# STM32N657 register map
File version: 1.0
CPU: CM55 r0p1, little endian, no MPU, FPU, vendor SysTick, 8 interrupt priority bits
Registers are 32-bit, read-write, reset 0x0 unless marked. A register's access mark holds for its fields unless they carry their own. Offsets are from the block's base; [hi:lo] are bit positions; 'fields as' and 'values as' point back to an identical list.

## RTC — Real-time clock
Base 0x46004000
Same registers: RTC_S 0x56004000
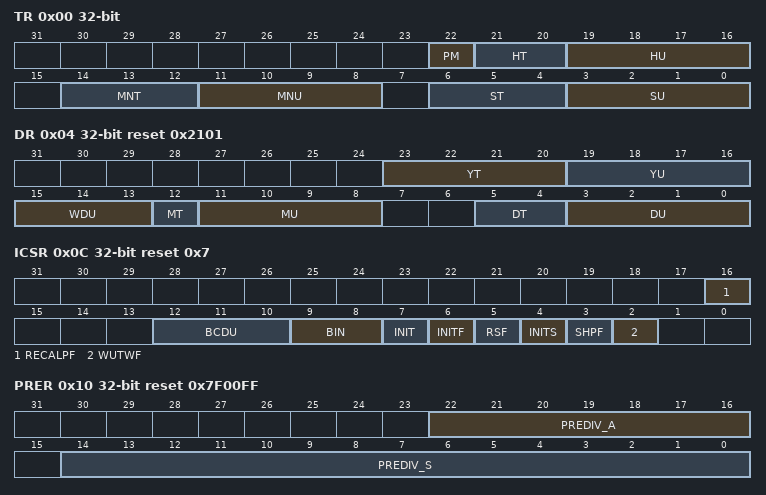
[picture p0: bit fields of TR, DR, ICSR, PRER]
0x00 TR — RTC time register
  [22] PM — AM/PM notation
  [21:20] HT — Hour tens in BCD format
  [19:16] HU — Hour units in BCD format
  [14:12] MNT — Minute tens in BCD format
  [11:8] MNU — Minute units in BCD format
  [6:4] ST — Second tens in BCD format
  [3:0] SU — Second units in BCD format
0x04 DR reset 0x2101 — RTC date register
  [23:20] YT — Year tens in BCD format
  [19:16] YU — Year units in BCD format
  [15:13] WDU — Week day units
  [12] MT — Month tens in BCD format
  [11:8] MU — Month units in BCD format
  [5:4] DT — Date tens in BCD format
  [3:0] DU — Date units in BCD format
0x08 SSR ro — RTC subsecond register
  [31:0] SS — Synchronous binary counter
0x0C ICSR access per field reset 0x7 — RTC initialization control and status register
  [16] RECALPF ro — Recalibration pending Flag
  [12:10] BCDU rw — BCD update (BIN = 10 or 11)
  [9:8] BIN rw — Binary mode
  [7] INIT rw — Initialization mode
  [6] INITF ro — Initialization flag
  [5] RSF rw — Registers synchronization flag
  [4] INITS ro — Initialization status flag
  [3] SHPF ro — Shift operation pending
  [2] WUTWF ro — Wake-up timer write flag
0x10 PRER reset 0x7F00FF — RTC prescaler register
  [22:16] PREDIV_A — Asynchronous prescaler factor
  [14:0] PREDIV_S — Synchronous prescaler factor
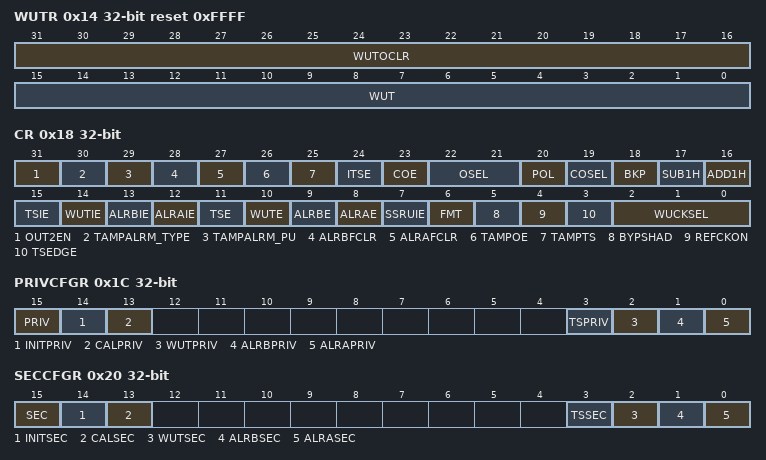
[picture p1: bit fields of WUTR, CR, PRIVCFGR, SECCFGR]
0x14 WUTR reset 0xFFFF — RTC wake-up timer register
  [31:16] WUTOCLR — Wake-up auto-reload output clear value
  [15:0] WUT — Wake-up auto-reload value bits
0x18 CR access per field — RTC control register
  [31] OUT2EN rw — RTC_OUT2 output enable
  [30] TAMPALRM_TYPE rw — TAMPALRM output type
  [29] TAMPALRM_PU rw — TAMPALRM pull-up enable
  [28] ALRBFCLR rw — Alarm B flag automatic clear
  [27] ALRAFCLR rw — Alarm A flag automatic clear
  [26] TAMPOE rw — Tamper detection output enable on TAMPALRM
  [25] TAMPTS rw — Activate timestamp on tamper detection event
  [24] ITSE rw — timestamp on internal event enable
  [23] COE rw — Calibration output enable
  [22:21] OSEL rw — Output selection
  [20] POL rw — Output polarity
  [19] COSEL rw — Calibration output selection
  [18] BKP rw — Backup
  [17] SUB1H wo — Subtract 1 hour (winter time change)
  [16] ADD1H wo — Add 1 hour (summer time change)
  [15] TSIE rw — Timestamp interrupt enable
  [14] WUTIE rw — Wake-up timer interrupt enable
  [13] ALRBIE rw — Alarm B interrupt enable
  [12] ALRAIE rw — Alarm A interrupt enable
  [11] TSE rw — timestamp enable
  [10] WUTE rw — Wake-up timer enable
  [9] ALRBE rw — Alarm B enable
  [8] ALRAE rw — Alarm A enable
  [7] SSRUIE rw — SSR underflow interrupt enable
  [6] FMT rw — Hour format
  [5] BYPSHAD rw — Bypass the shadow registers
  [4] REFCKON rw — RTC_REFIN reference clock detection enable (50 or 60 Hz)
  [3] TSEDGE rw — Timestamp event active edge
  [2:0] WUCKSEL rw — ck_wut wake-up clock selection
0x1C PRIVCFGR — RTC privilege mode control register
  [15] PRIV — RTC privilege protection
  [14] INITPRIV — Initialization privilege protection
  [13] CALPRIV — Shift register, Delight saving, calibration and reference clock privilege protection
  [3] TSPRIV — Timestamp privilege protection
  [2] WUTPRIV — Wake-up timer privilege protection
  [1] ALRBPRIV — Alarm B privilege protection
  [0] ALRAPRIV — Alarm A and SSR underflow privilege protection
0x20 SECCFGR — RTC secure configuration register
  [15] SEC — RTC global protection
  [14] INITSEC — Initialization protection
  [13] CALSEC — Shift register, daylight saving, calibration and reference clock protection
  [3] TSSEC — Timestamp protection
  [2] WUTSEC — Wake-up timer protection
  [1] ALRBSEC — Alarm B protection
  [0] ALRASEC — Alarm A and SSR underflow protection
0x24 WPR wo — RTC write protection register
  [7:0] KEY — Write protection key
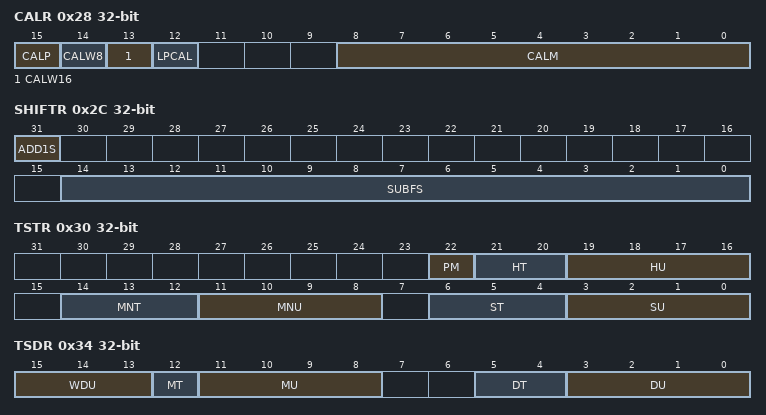
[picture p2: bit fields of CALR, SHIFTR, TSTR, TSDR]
0x28 CALR — RTC calibration register
  [15] CALP — Increase frequency of RTC by 488.5 ppm
  [14] CALW8 — Use an 8-second calibration cycle period
  [13] CALW16 — Use a 16-second calibration cycle period
  [12] LPCAL — RTC low-power mode
  [8:0] CALM — Calibration minus
0x2C SHIFTR wo — RTC shift control register
  [31] ADD1S — Add one second
  [14:0] SUBFS — Subtract a fraction of a second
0x30 TSTR ro — RTC timestamp time register
  [22] PM — AM/PM notation
  [21:20] HT — Hour tens in BCD format.
  [19:16] HU — Hour units in BCD format.
  [14:12] MNT — Minute tens in BCD format.
  [11:8] MNU — Minute units in BCD format.
  [6:4] ST — Second tens in BCD format.
  [3:0] SU — Second units in BCD format.
0x34 TSDR ro — RTC timestamp date register
  [15:13] WDU — Week day units
  [12] MT — Month tens in BCD format
  [11:8] MU — Month units in BCD format
  [5:4] DT — Date tens in BCD format
  [3:0] DU — Date units in BCD format
0x38 TSSSR ro — RTC timestamp subsecond register
  [31:0] SS — Subsecond value/synchronous binary counter values
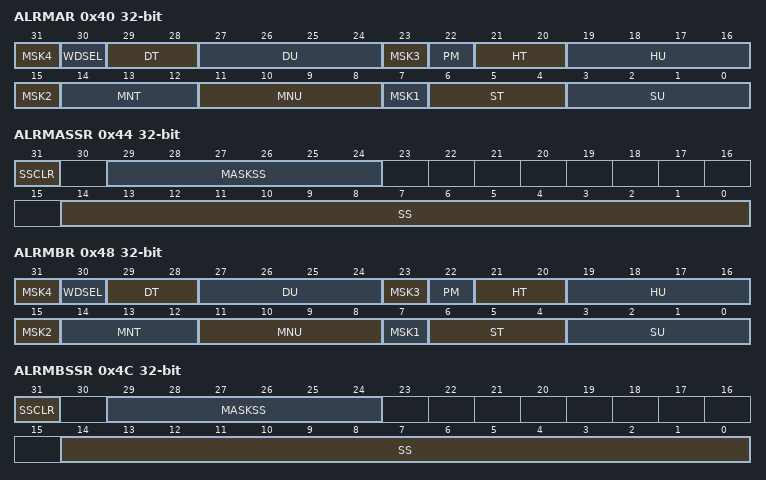
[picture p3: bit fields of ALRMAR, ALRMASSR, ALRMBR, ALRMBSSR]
0x40 ALRMAR — RTC alarm A register
  [31] MSK4 — Alarm A date mask
  [30] WDSEL — Week day selection
  [29:28] DT — Date tens in BCD format
  [27:24] DU — Date units or day in BCD format
  [23] MSK3 — Alarm A hours mask
  [22] PM — AM/PM notation
  [21:20] HT — Hour tens in BCD format
  [19:16] HU — Hour units in BCD format
  [15] MSK2 — Alarm A minutes mask
  [14:12] MNT — Minute tens in BCD format
  [11:8] MNU — Minute units in BCD format
  [7] MSK1 — Alarm A seconds mask
  [6:4] ST — Second tens in BCD format.
  [3:0] SU — Second units in BCD format.
0x44 ALRMASSR — RTC alarm A subsecond register
  [31] SSCLR — Clear synchronous counter on alarm (Binary mode only)
  [29:24] MASKSS — Mask the most-significant bits starting at this bit
  [14:0] SS — Subseconds value
0x48 ALRMBR — RTC alarm B register
  [31] MSK4 — Alarm B date mask
  [30] WDSEL — Week day selection
  [29:28] DT — Date tens in BCD format
  [27:24] DU — Date units or day in BCD format
  [23] MSK3 — Alarm B hours mask
  [22] PM — AM/PM notation
  [21:20] HT — Hour tens in BCD format
  [19:16] HU — Hour units in BCD format
  [15] MSK2 — Alarm B minutes mask
  [14:12] MNT — Minute tens in BCD format
  [11:8] MNU — Minute units in BCD format
  [7] MSK1 — Alarm B seconds mask
  [6:4] ST — Second tens in BCD format
  [3:0] SU — Second units in BCD format
0x4C ALRMBSSR — RTC alarm B subsecond register
  fields as ALRMASSR
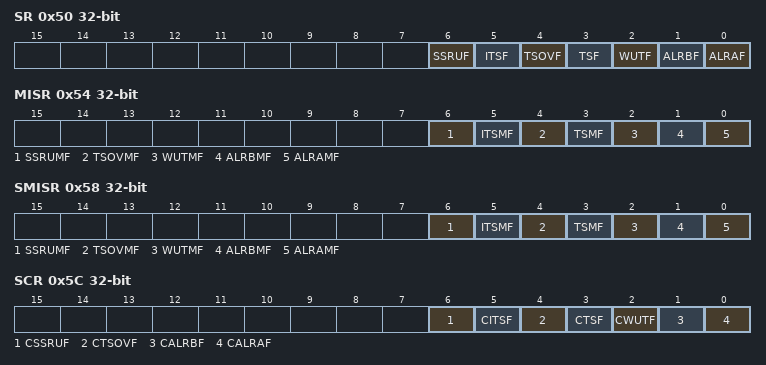
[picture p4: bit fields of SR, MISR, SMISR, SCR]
0x50 SR ro — RTC status register
  [6] SSRUF — SSR underflow flag
  [5] ITSF — Internal timestamp flag
  [4] TSOVF — Timestamp overflow flag
  [3] TSF — Timestamp flag
  [2] WUTF — Wake-up timer flag
  [1] ALRBF — Alarm B flag
  [0] ALRAF — Alarm A flag
0x54 MISR ro — RTC non-secure masked interrupt status register
  [6] SSRUMF — SSR underflow non-secure masked flag
  [5] ITSMF — Internal timestamp non-secure masked flag
  [4] TSOVMF — Timestamp overflow non-secure masked flag
  [3] TSMF — Timestamp non-secure masked flag
  [2] WUTMF — Wake-up timer non-secure masked flag
  [1] ALRBMF — Alarm B non-secure masked flag
  [0] ALRAMF — Alarm A masked flag
0x58 SMISR ro — RTC secure masked interrupt status register
  [6] SSRUMF — SSR underflow secure masked flag
  [5] ITSMF — Internal timestamp interrupt secure masked flag
  [4] TSOVMF — Timestamp overflow interrupt secure masked flag
  [3] TSMF — Timestamp interrupt secure masked flag
  [2] WUTMF — Wake-up timer interrupt secure masked flag
  [1] ALRBMF — Alarm B interrupt secure masked flag
  [0] ALRAMF — Alarm A interrupt secure masked flag
0x5C SCR wo — RTC status clear register
  [6] CSSRUF — Clear SSR underflow flag
  [5] CITSF — Clear internal timestamp flag
  [4] CTSOVF — Clear timestamp overflow flag
  [3] CTSF — Clear timestamp flag
  [2] CWUTF — Clear wake-up timer flag
  [1] CALRBF — Clear alarm B flag
  [0] CALRAF — Clear alarm A flag
0x70 ALRABINR — RTC alarm A binary mode register
  [31:0] SS — Synchronous counter alarm value in Binary mode
0x74 ALRBBINR — RTC alarm B binary mode register
  [31:0] SS — Synchronous counter alarm value in Binary mode
